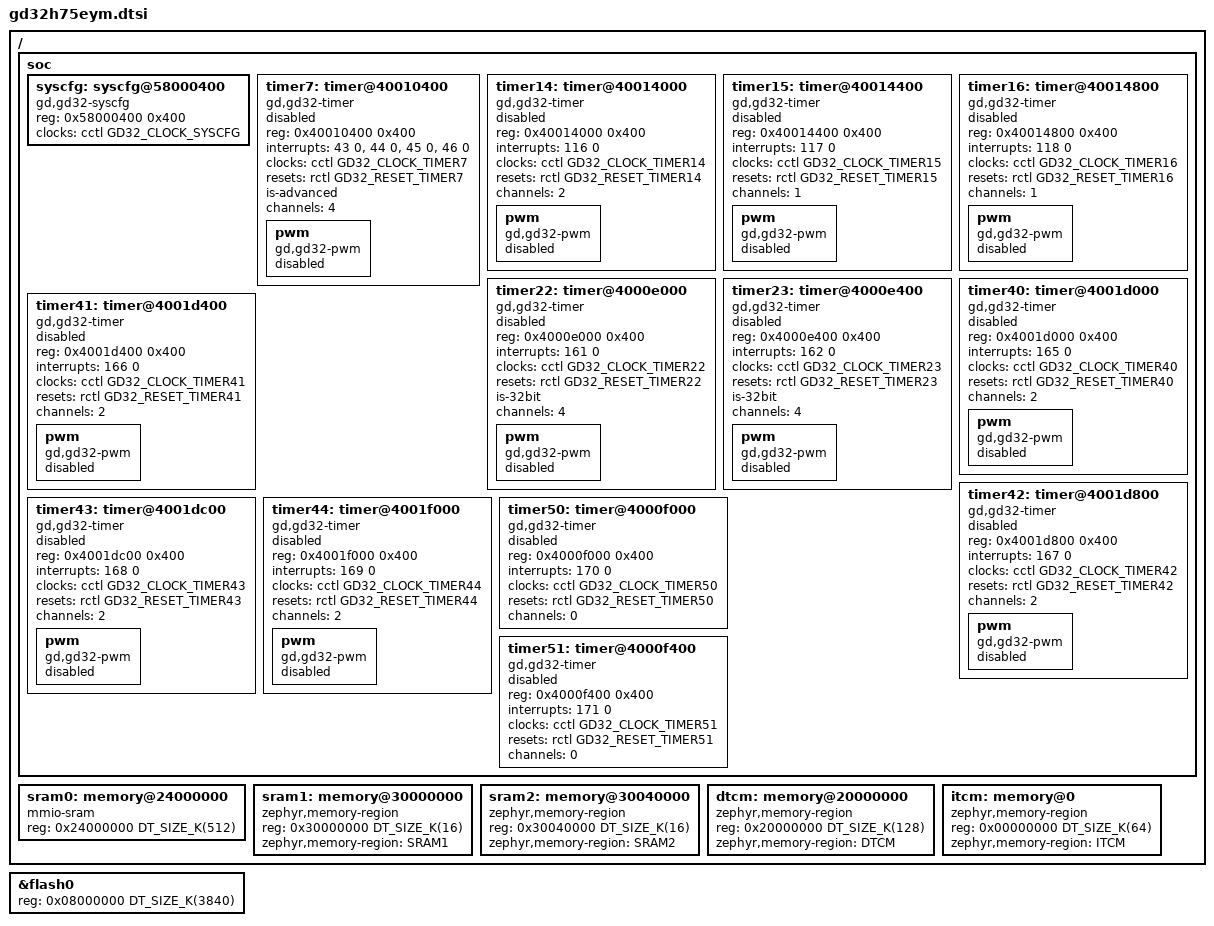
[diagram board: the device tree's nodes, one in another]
/*
 * Copyright (c) 2026 GigaDevice Semiconductor Inc.
 *
 * SPDX-License-Identifier: Apache-2.0
 */

#include <mem.h>
#include <arm/gd/gd32h75e/gd32h75e.dtsi>

/ {
	soc {
		syscfg: syscfg@58000400 {
			compatible = "gd,gd32-syscfg";
			reg = <0x58000400 0x400>;
			clocks = <&cctl GD32_CLOCK_SYSCFG>;
		};

		/* Additional USART instances specific to GD32H75EYM */
		/* Note: USART0-5, UART3-7 are defined in gd32h75e.dtsi */

		/* Additional I2C instances specific to GD32H75EYM */
		/* Note: I2C0-3 are defined in gd32h75e.dtsi */

		/* Additional SPI instances specific to GD32H75EYM */
		/* Note: SPI0-5 are defined in gd32h75e.dtsi */

		timer7: timer@40010400 {
			compatible = "gd,gd32-timer";
			reg = <0x40010400 0x400>;
			interrupts = <43 0>, <44 0>, <45 0>, <46 0>;
			interrupt-names = "brk", "up", "trgcom", "cc";
			clocks = <&cctl GD32_CLOCK_TIMER7>;
			resets = <&rctl GD32_RESET_TIMER7>;
			is-advanced;
			channels = <4>;
			status = "disabled";

			pwm {
				compatible = "gd,gd32-pwm";
				status = "disabled";
				#pwm-cells = <3>;
			};
		};

		timer14: timer@40014000 {
			compatible = "gd,gd32-timer";
			reg = <0x40014000 0x400>;
			interrupts = <116 0>;
			interrupt-names = "global";
			clocks = <&cctl GD32_CLOCK_TIMER14>;
			resets = <&rctl GD32_RESET_TIMER14>;
			channels = <2>;
			status = "disabled";

			pwm {
				compatible = "gd,gd32-pwm";
				status = "disabled";
				#pwm-cells = <3>;
			};
		};

		timer15: timer@40014400 {
			compatible = "gd,gd32-timer";
			reg = <0x40014400 0x400>;
			interrupts = <117 0>;
			interrupt-names = "global";
			clocks = <&cctl GD32_CLOCK_TIMER15>;
			resets = <&rctl GD32_RESET_TIMER15>;
			channels = <1>;
			status = "disabled";

			pwm {
				compatible = "gd,gd32-pwm";
				status = "disabled";
				#pwm-cells = <3>;
			};
		};

		timer16: timer@40014800 {
			compatible = "gd,gd32-timer";
			reg = <0x40014800 0x400>;
			interrupts = <118 0>;
			interrupt-names = "global";
			clocks = <&cctl GD32_CLOCK_TIMER16>;
			resets = <&rctl GD32_RESET_TIMER16>;
			channels = <1>;
			status = "disabled";

			pwm {
				compatible = "gd,gd32-pwm";
				status = "disabled";
				#pwm-cells = <3>;
			};
		};

		timer22: timer@4000e000 {
			compatible = "gd,gd32-timer";
			reg = <0x4000e000 0x400>;
			interrupts = <161 0>;
			interrupt-names = "global";
			clocks = <&cctl GD32_CLOCK_TIMER22>;
			resets = <&rctl GD32_RESET_TIMER22>;
			is-32bit;
			channels = <4>;
			status = "disabled";

			pwm {
				compatible = "gd,gd32-pwm";
				status = "disabled";
				#pwm-cells = <3>;
			};
		};

		timer23: timer@4000e400 {
			compatible = "gd,gd32-timer";
			reg = <0x4000e400 0x400>;
			interrupts = <162 0>;
			interrupt-names = "global";
			clocks = <&cctl GD32_CLOCK_TIMER23>;
			resets = <&rctl GD32_RESET_TIMER23>;
			is-32bit;
			channels = <4>;
			status = "disabled";

			pwm {
				compatible = "gd,gd32-pwm";
				status = "disabled";
				#pwm-cells = <3>;
			};
		};

		timer40: timer@4001d000 {
			compatible = "gd,gd32-timer";
			reg = <0x4001d000 0x400>;
			interrupts = <165 0>;
			interrupt-names = "global";
			clocks = <&cctl GD32_CLOCK_TIMER40>;
			resets = <&rctl GD32_RESET_TIMER40>;
			channels = <2>;
			status = "disabled";

			pwm {
				compatible = "gd,gd32-pwm";
				status = "disabled";
				#pwm-cells = <3>;
			};
		};

		timer41: timer@4001d400 {
			compatible = "gd,gd32-timer";
			reg = <0x4001d400 0x400>;
			interrupts = <166 0>;
			interrupt-names = "global";
			clocks = <&cctl GD32_CLOCK_TIMER41>;
			resets = <&rctl GD32_RESET_TIMER41>;
			channels = <2>;
			status = "disabled";

			pwm {
				compatible = "gd,gd32-pwm";
				status = "disabled";
				#pwm-cells = <3>;
			};
		};

		timer42: timer@4001d800 {
			compatible = "gd,gd32-timer";
			reg = <0x4001d800 0x400>;
			interrupts = <167 0>;
			interrupt-names = "global";
			clocks = <&cctl GD32_CLOCK_TIMER42>;
			resets = <&rctl GD32_RESET_TIMER42>;
			channels = <2>;
			status = "disabled";

			pwm {
				compatible = "gd,gd32-pwm";
				status = "disabled";
				#pwm-cells = <3>;
			};
		};

		timer43: timer@4001dc00 {
			compatible = "gd,gd32-timer";
			reg = <0x4001dc00 0x400>;
			interrupts = <168 0>;
			interrupt-names = "global";
			clocks = <&cctl GD32_CLOCK_TIMER43>;
			resets = <&rctl GD32_RESET_TIMER43>;
			channels = <2>;
			status = "disabled";

			pwm {
				compatible = "gd,gd32-pwm";
				status = "disabled";
				#pwm-cells = <3>;
			};
		};

		timer44: timer@4001f000 {
			compatible = "gd,gd32-timer";
			reg = <0x4001f000 0x400>;
			interrupts = <169 0>;
			interrupt-names = "global";
			clocks = <&cctl GD32_CLOCK_TIMER44>;
			resets = <&rctl GD32_RESET_TIMER44>;
			channels = <2>;
			status = "disabled";

			pwm {
				compatible = "gd,gd32-pwm";
				status = "disabled";
				#pwm-cells = <3>;
			};
		};

		timer50: timer@4000f000 {
			compatible = "gd,gd32-timer";
			reg = <0x4000f000 0x400>;
			interrupts = <170 0>;
			interrupt-names = "global";
			clocks = <&cctl GD32_CLOCK_TIMER50>;
			resets = <&rctl GD32_RESET_TIMER50>;
			channels = <0>;
			status = "disabled";
		};

		timer51: timer@4000f400 {
			compatible = "gd,gd32-timer";
			reg = <0x4000f400 0x400>;
			interrupts = <171 0>;
			interrupt-names = "global";
			clocks = <&cctl GD32_CLOCK_TIMER51>;
			resets = <&rctl GD32_RESET_TIMER51>;
			channels = <0>;
			status = "disabled";
		};

	};

	/* AXI SRAM (512 KB dedicated) */
	sram0: memory@24000000 {
		reg = <0x24000000 DT_SIZE_K(512)>;
		compatible = "mmio-sram";
	};

	/* SRAM0 (16 KB) */
	sram1: memory@30000000 {
		reg = <0x30000000 DT_SIZE_K(16)>;
		compatible = "zephyr,memory-region", "mmio-sram";
		zephyr,memory-region = "SRAM1";
	};

	/* SRAM1 (16 KB) */
	sram2: memory@30040000 {
		reg = <0x30040000 DT_SIZE_K(16)>;
		compatible = "zephyr,memory-region", "mmio-sram";
		zephyr,memory-region = "SRAM2";
	};

	/* Data TCM RAM (128 KB, factory default from shared RAM) */
	dtcm: memory@20000000 {
		compatible = "zephyr,memory-region", "arm,dtcm";
		reg = <0x20000000 DT_SIZE_K(128)>;
		zephyr,memory-region = "DTCM";
	};

	/* Instruction TCM RAM (64 KB) */
	itcm: memory@0 {
		compatible = "zephyr,memory-region", "arm,itcm";
		reg = <0x00000000 DT_SIZE_K(64)>;
		zephyr,memory-region = "ITCM";
	};

};

&flash0 {
	reg = <0x08000000 DT_SIZE_K(3840)>;
};
